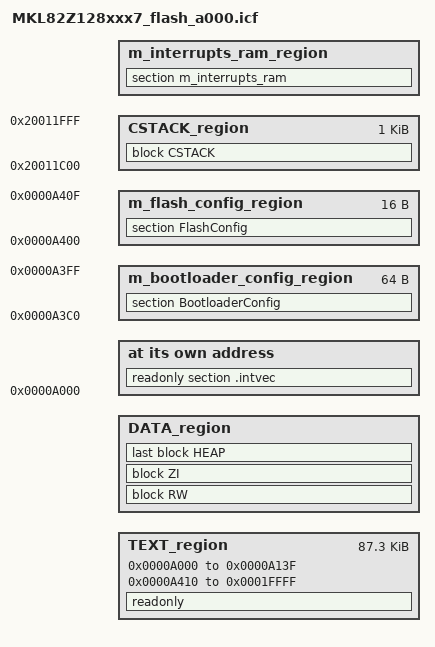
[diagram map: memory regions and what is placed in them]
/*
** ###################################################################
**     Processors:          MKL82Z128VLH7
**                          MKL82Z128VLK7
**                          MKL82Z128VLL7
**                          MKL82Z128VMC7
**                          MKL82Z128VMP7
**
**     Compiler:            IAR ANSI C/C++ Compiler for ARM
**     Reference manual:    KL82P121M72SF0RM, Rev.2 November 2015
**     Version:             rev. 1.5, 2015-09-24
**     Build:               b171205
**
**     Abstract:
**         Linker file for the IAR ANSI C/C++ Compiler for ARM
**
**     Copyright (c) 2015 Freescale Semiconductor, Inc.
**     Copyright 2016-2018 NXP
**     All rights reserved.
**
**     SPDX-License-Identifier: BSD-3-Clause
**
**     http:                 www.nxp.com
**     mail:                 support@nxp.com
**
** ###################################################################
*/

define symbol __ram_vector_table_size__ =  isdefinedsymbol(__ram_vector_table__) ? 0x00000140 : 0;
define symbol __ram_vector_table_offset__ =  isdefinedsymbol(__ram_vector_table__) ? 0x0000013F : 0;

define symbol m_interrupts_start       = 0x0000a000;
define symbol m_interrupts_end         = 0x0000a13F;

define symbol m_bootloader_config_start = 0x0000a3C0;
define symbol m_bootloader_config_end  = 0x0000a3FF;

define symbol m_flash_config_start     = 0x0000a400;
define symbol m_flash_config_end       = 0x0000a40F;

define symbol m_text_start             = 0x0000a410;
define symbol m_text_end               = 0x0001FFFF;

define symbol m_interrupts_ram_start   = 0x1FFFA000;
define symbol m_interrupts_ram_end     = 0x1FFFA000 + __ram_vector_table_offset__;

define symbol m_data_start             = m_interrupts_ram_start + __ram_vector_table_size__;
define symbol m_data_end               = 0x20011FFF;

/* Sizes */
if (isdefinedsymbol(__stack_size__)) {
  define symbol __size_cstack__        = __stack_size__;
} else {
  define symbol __size_cstack__        = 0x0400;
}

if (isdefinedsymbol(__heap_size__)) {
  define symbol __size_heap__          = __heap_size__;
} else {
  define symbol __size_heap__          = 0x0;
}

define exported symbol __VECTOR_TABLE  = m_interrupts_start;
define exported symbol __VECTOR_RAM    = isdefinedsymbol(__ram_vector_table__) ? m_interrupts_ram_start : m_interrupts_start;
define exported symbol __RAM_VECTOR_TABLE_SIZE = __ram_vector_table_size__;

define memory mem with size = 4G;
define region m_bootloader_config_region = mem:[from m_bootloader_config_start to m_bootloader_config_end];
define region m_flash_config_region = mem:[from m_flash_config_start to m_flash_config_end];
define region TEXT_region = mem:[from m_interrupts_start to m_interrupts_end]
                          | mem:[from m_text_start to m_text_end];
define region DATA_region = mem:[from m_data_start to m_data_end-__size_cstack__];
define region CSTACK_region = mem:[from m_data_end-__size_cstack__+1 to m_data_end];
define region m_interrupts_ram_region = mem:[from m_interrupts_ram_start to m_interrupts_ram_end];

define block CSTACK    with alignment = 8, size = __size_cstack__   { };
define block HEAP      with alignment = 8, size = __size_heap__     { };
define block RW        { readwrite };
define block ZI        { zi };

initialize by copy { readwrite, section .textrw };
do not initialize  { section .noinit };

place at address mem: m_interrupts_start    { readonly section .intvec };
place in m_bootloader_config_region         { section BootloaderConfig };
place in m_flash_config_region              { section FlashConfig };
place in TEXT_region                        { readonly };
place in DATA_region                        { block RW };
place in DATA_region                        { block ZI };
place in DATA_region                        { last block HEAP };
place in CSTACK_region                      { block CSTACK };
place in m_interrupts_ram_region            { section m_interrupts_ram };

